# ioam3358 register map
Registers are 32-bit, access not given, no defined reset value unless marked. A register's access mark holds for its fields unless they carry their own. Addresses are absolute; registers are grouped by the start of their names; [hi:lo] are bit positions.

## DMTIMER1
0x44E31000 DMTIMER1_1MS_TIDR
  [7:0] TID_REV
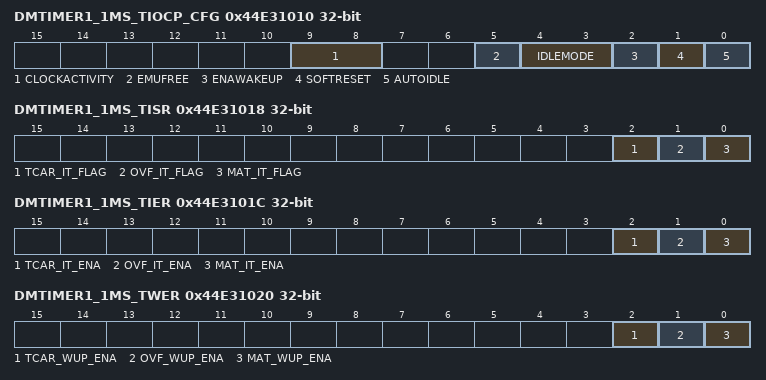
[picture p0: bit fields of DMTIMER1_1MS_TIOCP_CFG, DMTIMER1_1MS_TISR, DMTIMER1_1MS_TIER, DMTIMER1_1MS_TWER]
0x44E31010 DMTIMER1_1MS_TIOCP_CFG
  [9:8] CLOCKACTIVITY, [5] EMUFREE, [4:3] IDLEMODE, [2] ENAWAKEUP, [1] SOFTRESET, [0] AUTOIDLE
0x44E31014 DMTIMER1_1MS_TISTAT
  [0] RESETDONE
0x44E31018 DMTIMER1_1MS_TISR
  [2] TCAR_IT_FLAG, [1] OVF_IT_FLAG, [0] MAT_IT_FLAG
0x44E3101C DMTIMER1_1MS_TIER
  [2] TCAR_IT_ENA, [1] OVF_IT_ENA, [0] MAT_IT_ENA
0x44E31020 DMTIMER1_1MS_TWER
  [2] TCAR_WUP_ENA, [1] OVF_WUP_ENA, [0] MAT_WUP_ENA
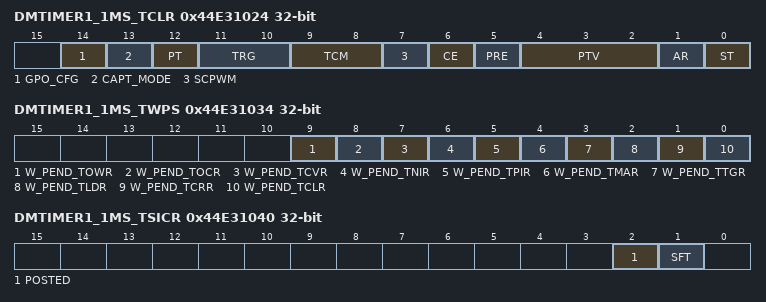
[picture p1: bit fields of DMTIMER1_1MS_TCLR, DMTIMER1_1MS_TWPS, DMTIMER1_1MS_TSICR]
0x44E31024 DMTIMER1_1MS_TCLR
  [14] GPO_CFG, [13] CAPT_MODE, [12] PT, [11:10] TRG, [9:8] TCM, [7] SCPWM, [6] CE, [5] PRE, [4:2] PTV, [1] AR, [0] ST
0x44E31028 DMTIMER1_1MS_TCRR
0x44E3102C DMTIMER1_1MS_TLDR
0x44E31030 DMTIMER1_1MS_TTGR
0x44E31034 DMTIMER1_1MS_TWPS
  [9] W_PEND_TOWR, [8] W_PEND_TOCR, [7] W_PEND_TCVR, [6] W_PEND_TNIR, [5] W_PEND_TPIR, [4] W_PEND_TMAR, [3] W_PEND_TTGR, [2] W_PEND_TLDR, [1] W_PEND_TCRR, [0] W_PEND_TCLR
0x44E31038 DMTIMER1_1MS_TMAR
0x44E3103C DMTIMER1_1MS_TCAR1
0x44E31040 DMTIMER1_1MS_TSICR
  [2] POSTED, [1] SFT
0x44E31044 DMTIMER1_1MS_TCAR2
0x44E31048 DMTIMER1_1MS_TPIR
0x44E3104C DMTIMER1_1MS_TNIR
0x44E31050 DMTIMER1_1MS_TCVR
0x44E31054 DMTIMER1_1MS_TOCR
  [23:0] OVF_COUNTER_VALUE
0x44E31058 DMTIMER1_1MS_TOWR
  [23:0] OVF_WRAPPING_VALUE

## DMTIMER2
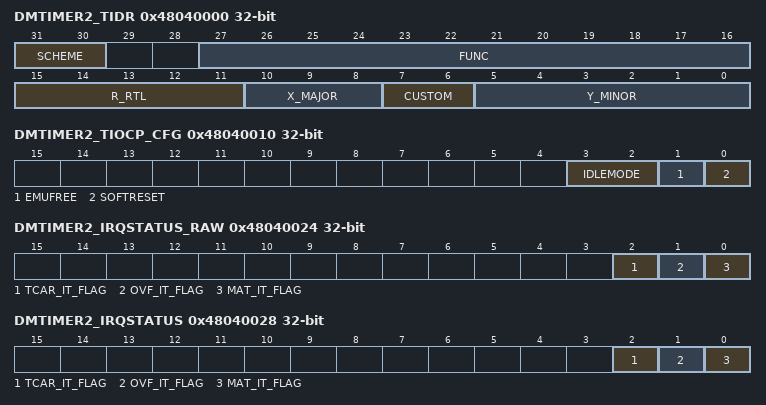
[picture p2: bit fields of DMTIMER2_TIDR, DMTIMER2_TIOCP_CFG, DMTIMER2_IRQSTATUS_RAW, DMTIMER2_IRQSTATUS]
0x48040000 DMTIMER2_TIDR
  [31:30] SCHEME, [27:16] FUNC, [15:11] R_RTL, [10:8] X_MAJOR, [7:6] CUSTOM, [5:0] Y_MINOR
0x48040010 DMTIMER2_TIOCP_CFG
  [3:2] IDLEMODE, [1] EMUFREE, [0] SOFTRESET
0x48040020 DMTIMER2_IRQ_EOI
  [0] LINE_NUMBER
0x48040024 DMTIMER2_IRQSTATUS_RAW
  [2] TCAR_IT_FLAG, [1] OVF_IT_FLAG, [0] MAT_IT_FLAG
0x48040028 DMTIMER2_IRQSTATUS
  [2] TCAR_IT_FLAG, [1] OVF_IT_FLAG, [0] MAT_IT_FLAG
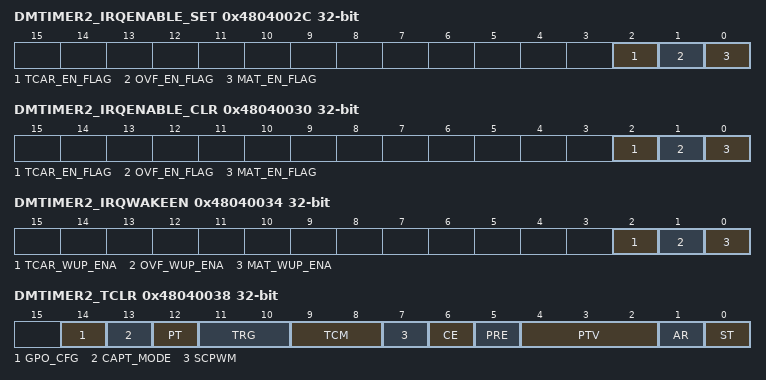
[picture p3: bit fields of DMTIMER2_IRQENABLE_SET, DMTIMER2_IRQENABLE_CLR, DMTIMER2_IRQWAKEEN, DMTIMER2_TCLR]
0x4804002C DMTIMER2_IRQENABLE_SET
  [2] TCAR_EN_FLAG, [1] OVF_EN_FLAG, [0] MAT_EN_FLAG
0x48040030 DMTIMER2_IRQENABLE_CLR
  [2] TCAR_EN_FLAG, [1] OVF_EN_FLAG, [0] MAT_EN_FLAG
0x48040034 DMTIMER2_IRQWAKEEN
  [2] TCAR_WUP_ENA, [1] OVF_WUP_ENA, [0] MAT_WUP_ENA
0x48040038 DMTIMER2_TCLR
  [14] GPO_CFG, [13] CAPT_MODE, [12] PT, [11:10] TRG, [9:8] TCM, [7] SCPWM, [6] CE, [5] PRE, [4:2] PTV, [1] AR, [0] ST
0x4804003C DMTIMER2_TCRR
0x48040040 DMTIMER2_TLDR
0x48040044 DMTIMER2_TTGR
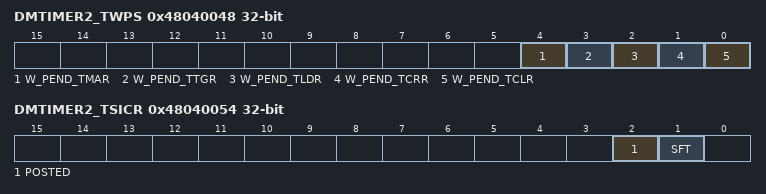
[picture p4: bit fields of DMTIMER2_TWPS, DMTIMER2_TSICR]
0x48040048 DMTIMER2_TWPS
  [4] W_PEND_TMAR, [3] W_PEND_TTGR, [2] W_PEND_TLDR, [1] W_PEND_TCRR, [0] W_PEND_TCLR
0x4804004C DMTIMER2_TMAR
0x48040050 DMTIMER2_TCAR1
0x48040054 DMTIMER2_TSICR
  [2] POSTED, [1] SFT
0x48040058 DMTIMER2_TCAR2

## DMTIMER3
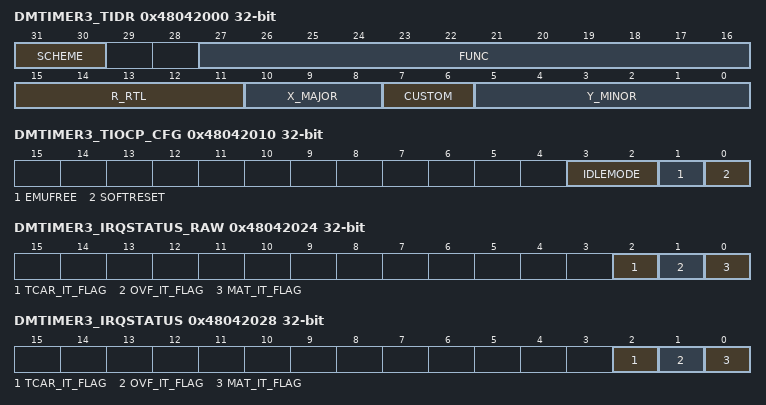
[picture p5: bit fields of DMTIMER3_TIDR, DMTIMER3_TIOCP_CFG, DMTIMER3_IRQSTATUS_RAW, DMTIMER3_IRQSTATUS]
0x48042000 DMTIMER3_TIDR
  [31:30] SCHEME, [27:16] FUNC, [15:11] R_RTL, [10:8] X_MAJOR, [7:6] CUSTOM, [5:0] Y_MINOR
0x48042010 DMTIMER3_TIOCP_CFG
  [3:2] IDLEMODE, [1] EMUFREE, [0] SOFTRESET
0x48042020 DMTIMER3_IRQ_EOI
  [0] LINE_NUMBER
0x48042024 DMTIMER3_IRQSTATUS_RAW
  [2] TCAR_IT_FLAG, [1] OVF_IT_FLAG, [0] MAT_IT_FLAG
0x48042028 DMTIMER3_IRQSTATUS
  [2] TCAR_IT_FLAG, [1] OVF_IT_FLAG, [0] MAT_IT_FLAG
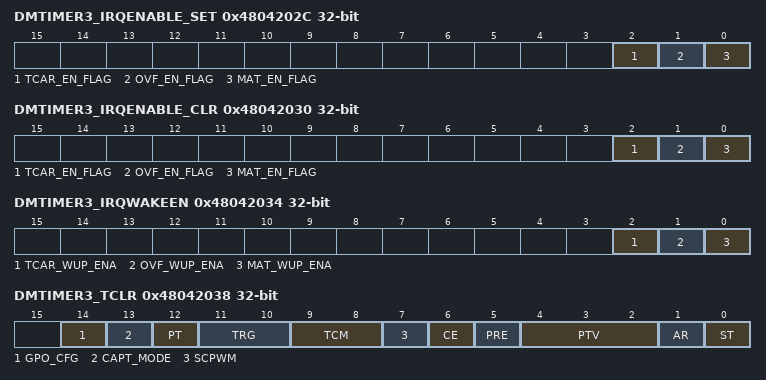
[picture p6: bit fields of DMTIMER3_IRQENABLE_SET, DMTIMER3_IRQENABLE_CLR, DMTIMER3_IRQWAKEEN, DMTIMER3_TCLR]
0x4804202C DMTIMER3_IRQENABLE_SET
  [2] TCAR_EN_FLAG, [1] OVF_EN_FLAG, [0] MAT_EN_FLAG
0x48042030 DMTIMER3_IRQENABLE_CLR
  [2] TCAR_EN_FLAG, [1] OVF_EN_FLAG, [0] MAT_EN_FLAG
0x48042034 DMTIMER3_IRQWAKEEN
  [2] TCAR_WUP_ENA, [1] OVF_WUP_ENA, [0] MAT_WUP_ENA
0x48042038 DMTIMER3_TCLR
  [14] GPO_CFG, [13] CAPT_MODE, [12] PT, [11:10] TRG, [9:8] TCM, [7] SCPWM, [6] CE, [5] PRE, [4:2] PTV, [1] AR, [0] ST
0x4804203C DMTIMER3_TCRR
0x48042040 DMTIMER3_TLDR
0x48042044 DMTIMER3_TTGR
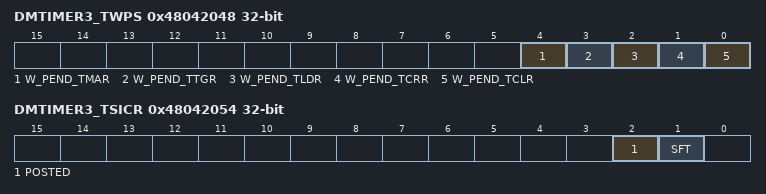
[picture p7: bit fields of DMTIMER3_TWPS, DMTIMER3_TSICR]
0x48042048 DMTIMER3_TWPS
  [4] W_PEND_TMAR, [3] W_PEND_TTGR, [2] W_PEND_TLDR, [1] W_PEND_TCRR, [0] W_PEND_TCLR
0x4804204C DMTIMER3_TMAR
0x48042050 DMTIMER3_TCAR1
0x48042054 DMTIMER3_TSICR
  [2] POSTED, [1] SFT
0x48042058 DMTIMER3_TCAR2

## DMTIMER4
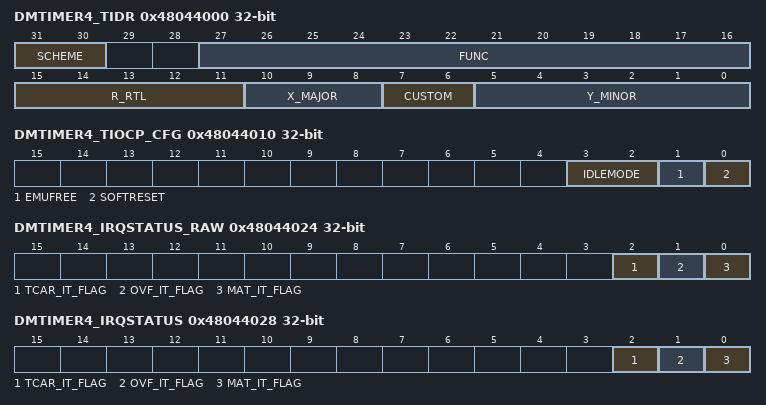
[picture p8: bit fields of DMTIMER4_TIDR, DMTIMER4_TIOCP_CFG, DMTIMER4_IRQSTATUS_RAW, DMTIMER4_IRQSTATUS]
0x48044000 DMTIMER4_TIDR
  [31:30] SCHEME, [27:16] FUNC, [15:11] R_RTL, [10:8] X_MAJOR, [7:6] CUSTOM, [5:0] Y_MINOR
0x48044010 DMTIMER4_TIOCP_CFG
  [3:2] IDLEMODE, [1] EMUFREE, [0] SOFTRESET
0x48044020 DMTIMER4_IRQ_EOI
  [0] LINE_NUMBER
0x48044024 DMTIMER4_IRQSTATUS_RAW
  [2] TCAR_IT_FLAG, [1] OVF_IT_FLAG, [0] MAT_IT_FLAG
0x48044028 DMTIMER4_IRQSTATUS
  [2] TCAR_IT_FLAG, [1] OVF_IT_FLAG, [0] MAT_IT_FLAG
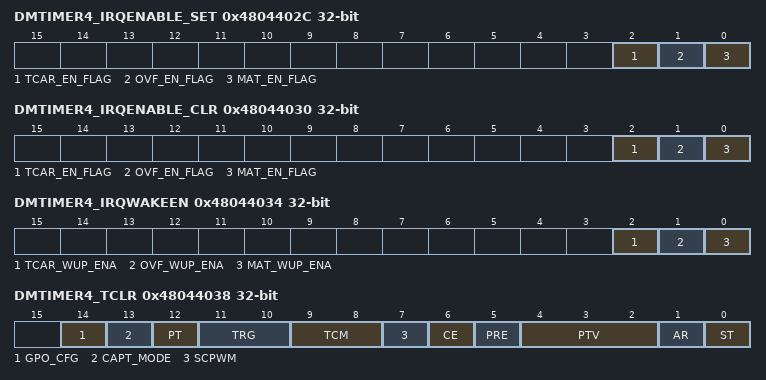
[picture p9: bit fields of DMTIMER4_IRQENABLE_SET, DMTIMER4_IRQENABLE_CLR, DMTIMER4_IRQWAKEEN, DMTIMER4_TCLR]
0x4804402C DMTIMER4_IRQENABLE_SET
  [2] TCAR_EN_FLAG, [1] OVF_EN_FLAG, [0] MAT_EN_FLAG
0x48044030 DMTIMER4_IRQENABLE_CLR
  [2] TCAR_EN_FLAG, [1] OVF_EN_FLAG, [0] MAT_EN_FLAG
0x48044034 DMTIMER4_IRQWAKEEN
  [2] TCAR_WUP_ENA, [1] OVF_WUP_ENA, [0] MAT_WUP_ENA
0x48044038 DMTIMER4_TCLR
  [14] GPO_CFG, [13] CAPT_MODE, [12] PT, [11:10] TRG, [9:8] TCM, [7] SCPWM, [6] CE, [5] PRE, [4:2] PTV, [1] AR, [0] ST
0x4804403C DMTIMER4_TCRR
0x48044040 DMTIMER4_TLDR
0x48044044 DMTIMER4_TTGR
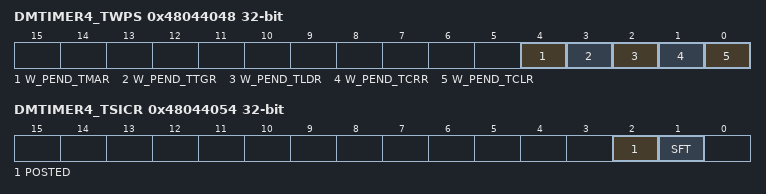
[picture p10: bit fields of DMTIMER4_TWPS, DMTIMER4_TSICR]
0x48044048 DMTIMER4_TWPS
  [4] W_PEND_TMAR, [3] W_PEND_TTGR, [2] W_PEND_TLDR, [1] W_PEND_TCRR, [0] W_PEND_TCLR
0x4804404C DMTIMER4_TMAR
0x48044050 DMTIMER4_TCAR1
0x48044054 DMTIMER4_TSICR
  [2] POSTED, [1] SFT
0x48044058 DMTIMER4_TCAR2
